# RS1xxxx register map
Vendor: Silicon Lab Inc.; Series: ARMCM4; File version: 1.2
CPU: CM4 r1p0, little endian, MPU, FPU, 6 interrupt priority bits
Registers are 32-bit, read-write, reset 0x0 unless marked. A register's access mark holds for its fields unless they carry their own. Offsets are from the block's base; [hi:lo] are bit positions; lines under a group give offsets from that group; {n}, {i} and the like mark numbered series; 'fields as' and 'values as' point back to an identical list.

## SIO — SERIAL GENERAL PERPOSE INPUT/OUTPUT
Base 0x47000000
0x00 SIO_ENABLE_REG — ENABLE REGISTER
  [15:0] SIO_OPERATION_ENABLE — Contains the Enables for all SIO
0x04 SIO_PAUSE_REG — PAUSE REGISTER
  [15:0] SIO_POSITION_COUNTER_DISABLE — Contains sio position counter disable for all SIOs
0x08 SIO_GPIO_IN_REG ro — GPIO Input Register
  [31:0] IN_VALUE — GPIO input pin status
0x0C SIO_GPIO_OUT_REG — GPIO Output Register
  [31:0] OUT_VALUE — Value to be loaded on GPIO out pins
0x10 SIO_GPIO_OEN_REG reset 0xFFFF — GPIO Output enable Register
  [31:0] OEN_VALUE — OEN for the GPIO pins
0x14 SIO_GPIO_INTR_EN_SET_REG — GPIO Interrupt Enable Set Register
  [15:0] INTR_ENABLE_SET wo — gpio interrupt enable set register for all SIOs
0x18 SIO_GPIO_INTR_EN_CLEAR_REG wo — GPIO Interrupt Enable Clear Register
  [15:0] INTR_ENABLE_CLEAR — gpio interrupt enable Clear register for all SIOs
0x1C SIO_GPIO_INTR_MASK_SET_REG reset 0xFFFF — GPIO Interrupt Enable Clear Register
  [15:0] INTR_MASK_SET — Common gpio interrupt mask set register for all SIOs
0x20 SIO_GPIO_INTR_MASK_CLEAR_REG wo reset 0xFFFF — GPIO Interrupt Enable Clear Register
  [15:0] INTR_MASK_CLEAR — gpio interrupt mask clear register for all SIOs
0x24 SIO_GPIO_INTR_STATUS_REG reset 0xFFFF — GPIO Interrupt Status Register
  [15:0] INTR_MASK_SET wo — Common gpio interrupt status register for all SIOs
{0x28+4i} SIO_SHIFT_COUNTERn[{i}] (i=0..15) group — Shift counter register
  0x00 SIO_SHIFT_COUNTER__n_ ro — Shift counter register
    [13:0] SHIFT_COUNTER — shift counter current value
{0x68+4i} SIO_BUFFER_REGn[{i}] (i=0..15) group — SIO Buffer registers
  0x00 SIO_BUFFER_REG__n_ — Buffer Register
    [31:0] DATA — Data to load into the shift register
{0xA8+4i} SIO_SHIFT_COUNT_PRELOAD_REGn[{i}] (i=0..15) group — SIO Shift count preload register
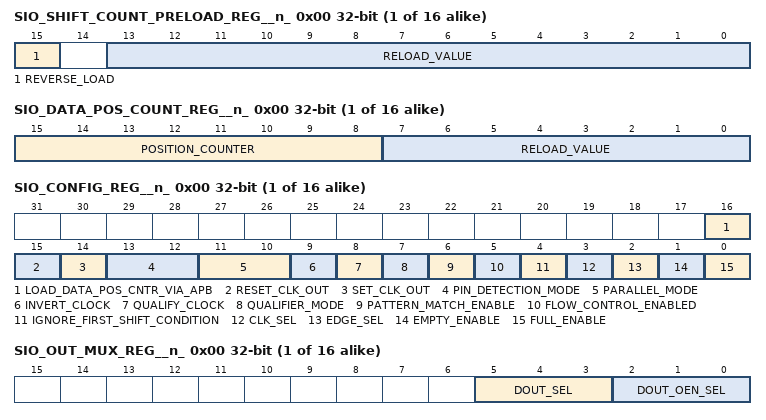
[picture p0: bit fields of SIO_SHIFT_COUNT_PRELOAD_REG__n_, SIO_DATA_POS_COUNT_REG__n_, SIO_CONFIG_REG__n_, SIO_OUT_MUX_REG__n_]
  0x00 SIO_SHIFT_COUNT_PRELOAD_REG__n_ — Shift counter preload Register
    [15] REVERSE_LOAD — When set, the data on APB is loaded to buffer is reverse order
    [13:0] RELOAD_VALUE — division factor required to generate shift clock
{0xE8+4i} SIO_DATA_POS_COUNT_REGn[{i}] (i=0..15) group — SIO DATA position count registers
  0x00 SIO_DATA_POS_COUNT_REG__n_ — Data Position Counter Register
    [15:8] POSITION_COUNTER — The position counter can be loaded via AHB
    [7:0] RELOAD_VALUE — No. of shifts to happen before reloading the shift register with data/ pausing the operation
{0x128+4i} SIO_CONFIG_REGn[{i}] (i=0..15) group — SIO Configuration Registers 0 to 15
  0x00 SIO_CONFIG_REG__n_ — Configuration Register
    [16] LOAD_DATA_POS_CNTR_VIA_APB — When set, data position counter can be loaded via APB
    [15] RESET_CLK_OUT — When high resets the sio clock_out port. This is used only when sio is not enabled
    [14] SET_CLK_OUT — When high sets the sio clock_out port. This is used only when sio is not enabled
    [13:12] PIN_DETECTION_MODE — Pin mode to be considered for gpio interrupt
      0=rise edge; 1=fall edge; 2=level zero; 3=level one
    [11:10] PARALLEL_MODE — No. of bits to shift/capture at valid clk edge
      0=1 bit; 1=2 bits; 2=4 bits; 3=8 bits
    [9] INVERT_CLOCK
      0=None (direct version of shift clock is provided out); 1=none (inverted version of the clock is provided out)
    [8] QUALIFY_CLOCK
      0=none (output clock is not qualified); 1=None (output clock is qualified with qualifier)
    [7] QUALIFIER_MODE
      0=none (Use direct qualifier input); 1=None (Use inverted qualifier)
    [6] PATTERN_MATCH_ENABLE — pattern match
      0=Disable (pattern match disable); 1=Enable (pattern match enable)
    [5] FLOW_CONTROL_ENABLED — flow control
      0=Disable (flow control disable); 1=Enable (flow control enable)
    [4] IGNORE_FIRST_SHIFT_CONDITION — data shift condition
      0=Disable (at a shift/capture happens at the first clock edge)
    [3] CLK_SEL — clock selection
      0=Disable (internal counter clock is used for shift operations and sent out); 1=Enable (external clock is used for shift operations and is sent out)
    [2] EDGE_SEL — edge selection
      0=Disable (pos edge); 1=Enable (neg edge)
    [1] EMPTY_ENABLE — When set, fifo full indication would be asserted when internal buffer is empty
    [0] FULL_ENABLE — When set, fifo full indication would be asserted when internal buffer is full
0x168 SIO_PATTERN_MATCH_MASK_REG_SLICE_0 — Pattern Match Mask Register 0
  [31:0] MATCH_MASK_LOWER16_BITS — Enable for lower 16 bits
0x16C SIO_PATTERN_MATCH_MASK_REG_SLICE_1 — Pattern Match Mask Register Slice 1
  [31:0] MATCH_MASK_LOWER16_BITS — Enable for lower 16 bits
0x170 SIO_PATTERN_MATCH_MASK_REG_SLICE_2 — Pattern Match Mask Register Slice 2
  [31:0] MATCH_MASK_LOWER16_BITS — Enable for lower 16 bits
{0x168+4i} SIO_PATTERN_MATCH_MASK_REG_SLICE_{i} (i=8..10) — Pattern Match Mask Register Slice {i}
  [31:0] MATCH_MASK_LOWER16_BITS — Enable for lower 16 bits
{0x1A8+4i} SIO_PATTERN_MATCH_REG_SLICE_{i} (i=0..2) — Pattern Match Mask Register Slice {i}
  [31:0] PATTERN_MATCH_LOWER16_BITS — Lower 16-bits of pattern to be detected
{0x1A8+4i} SIO_PATTERN_MATCH_REG_SLICE_{i} (i=8..10) — Pattern Match Mask Register Slice {i}
  [31:0] PATTERN_MATCH_LOWER16_BITS — Lower 16 bits of pattern to be detected
0x1F0 SIO_SHIFT_INTR_EN_SET_REG — Shift Interrupt Enable Set Register
  [15:0] INTR_ENABLE_SET — Common shift interrupt enable set register for all SIOs
0x1F4 SIO_SHIFT_INTR_EN_CLEAR_REG wo — Shift Interrupt Enable Clear Register
  [15:0] INRT_ENABLE_CLEAR — Common shift interrupt enable Clear register for all SIOs
0x1F8 SIO_SHIFT_INTR_MASK_SET_REG reset 0xFFFF — Shift Interrupt Mask Set Register
  [15:0] INTR_MASK_SET — Common shift interrupt enable Set register for all SIOs
0x1FC SIO_SHIFT_INTR_MASK_CLEAR_REG wo reset 0xFFFF — Shift Interrupt Mask Clear Register
  [15:0] INTR_MASK_CLEAR — Common shift interrupt mask clear register for all SIOs
0x200 SIO_SHIFT_INTR_STATUS_REG — Shift Interrupt Status Register
  [15:0] INTR_ENABLE_SET — Common shift interrupt mask clear register for all SIOs
0x204 SIO_SWAP_INTR_EN_SET_REG — Swap Interrupt Enable Set Register
  [15:0] INTR_ENABLE_SET — Swap interrupt enable set register for all SIOs
0x208 SIO_SWAP_INTR_EN_CLEAR_REG wo — Swap Interrupt Enable Clear Register
  [15:0] INTR_ENABLE_CLEAR — Swap interrupt enable Clear register for all SIOs
0x20C SIO_SWAP_INTR_MASK_SET_REG reset 0xFFFF — Swap Interrupt Mask Set Register
  [15:0] INTR_MASK_SET — Common swap interrupt mask set register for all SIOs
0x210 SIO_SWAP_INTR_MASK_CLEAR_REG wo reset 0xFFFF — Swap Interrupt Mask Clear Register
  [15:0] INTR_MASK_CLEAR — Common swap interrupt mask Clear register for all SIOs
0x214 SIO_SWAP_INTR_STATUS_REG — Swap Interrupt Statusr Register
  [15:0] INTR_ENABLE_SET — Common swap interrupt status register for all SIOs
0x218 SIO_PATTERN_MATCH_INTR_EN_SET_REG — Pattern Match Interrupt Enable Set Register
  [15:0] INTR_ENABLE_SET — Common pattern or buffer under run interrupt enable set register for all SIOs. Each bit corresponds to one SIO
0x21C SIO_PATTERN_MATCH_INTR_EN_CLEAR_REG wo — Pattern Match Interrupt Enable Clear Register
  [15:0] INRT_ENABLE_CLEAR — Common pattern or buffer under run interrupt enable clear register for all SIOs
0x220 SIO_PATTERN_MATCH_INTR_MASK_SET_REG reset 0xFFFF — Pattern Match Interrupt Mask Set Register
  [15:0] INTR_MASK_SET — Common pattern or buffer under run interrupt mask set register for all SIOs
0x224 SIO_PATTERN_MATCH_INTR_MASK_CLEAR_REG wo reset 0xFFFF — Pattern Match Interrupt Mask Clear Register
  [15:0] INTR_MASK_CLEAR — Common pattern or buffer under run interrupt mask clear register for all SIOs
0x228 SIO_PATTERN_MATCH_INTR_STATUS_REG — Pattern Match Interrupt Status Register
  [15:0] INTR_STATUS — Common pattern interrupt status register for all SIOs
0x22C SIO_BUFFER_INTR_STATUS_REG — Buffer Interrupt Status Register
  fields as SIO_PATTERN_MATCH_INTR_STATUS_REG
{0x230+4i} SIO_OUT_MUX_REGn[{i}] (i=0..15) group — SIO Output mux register
  0x00 SIO_OUT_MUX_REG__n_ — Output muxing Register
    [5:3] DOUT_SEL — Output mux select for GPIO pin 0
    [2:0] DOUT_OEN_SEL — OEN select for GPIO pin 0
{0x270+4i} SIO_INPUT_MUX_REGn[{i}] (i=0..15) group — SIO Input mux register
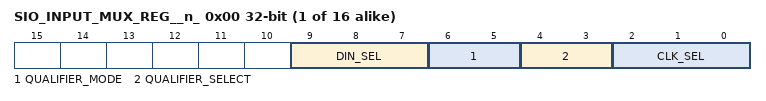
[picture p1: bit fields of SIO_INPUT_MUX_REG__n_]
  0x00 SIO_INPUT_MUX_REG__n_ — Input muxing Register
    [9:7] DIN_SEL — Data in mux select
    [6:5] QUALIFIER_MODE
    [4:3] QUALIFIER_SELECT
    [2:0] CLK_SEL — Input clock select for SIO 0
0x2B0 SIO_FIFO_WR_RD_REG — FIFO READ/WRITE Register
  [31:0] FIFO_DATA_REGISTER — Writes and read into this register will be written into SIO buffer register
0x2B4 SIO_FIFO_WR_OFFSET_START_REG — Points to start slice number forming the FIFO
  [31:0] SIO_START_SLICE_NUMBER — Points to start slice number forming the FIFO,On write, FIFO_WR_OFFSET_CNT_REG will also be reset to the value pointed written into this register
0x2B8 SIO_FIFO_WR_OFFSET_END_REG — SIO last slice no indication Register
  [31:0] SIO_END_SLICE_NUMBER — points to last slice no forming fifo
0x2BC SIO_FIFO_WR_OFFSET_CNT_REG — Points to current slice number forming the FIFO
  [31:0] SIO_CURRENT_SLICE_NUMBER — Next FIFO operation will happen to buffer in the slice pointed by this register
0x2C0 SIO_FIFO_RD_OFFSET_START_REG — Points to start slice number forming the FIFO
  [31:0] SIO_START_SLICE_NUMBER
0x2C4 SIO_FIFO_RD_OFFSET_END_REG — Points to last slice number forming the FIFO
  [31:0] SIO_END_SLICE_NUMBER
0x2C8 SIO_FIFO_RD_OFFSET_CNT_REG — Points to start current number forming the FIFO
  [31:0] SIO_CURRENT_SLICE_NUMBER — Next FIFO operation will happen to buffer in the slice pointed by this register This register has to be set to zero before starting fresh DMA operation
